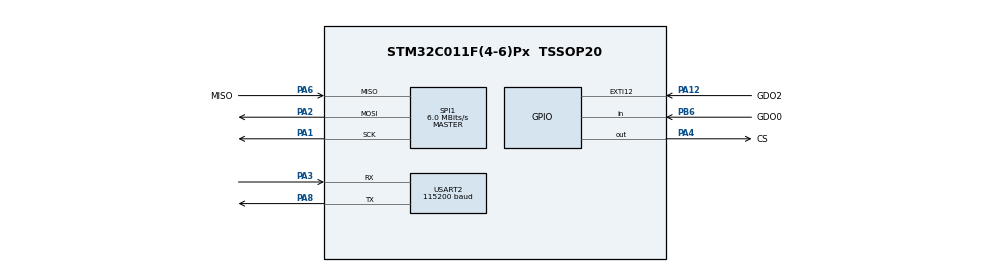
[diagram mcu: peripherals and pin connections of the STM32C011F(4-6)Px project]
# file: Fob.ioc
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Mcu.Family=STM32C0
Mcu.Name=STM32C011F(4-6)Px
Mcu.Package=TSSOP20
PA1.Mode=Full_Duplex_Master
PA1.Signal=SPI1_SCK
PA12\ [PA10].GPIO_Label=GDO2
PA12\ [PA10].Signal=GPXTI12
PA13.Mode=Serial_Wire
PA13.Signal=DEBUG_SWDIO
PA14-BOOT0.Mode=Serial_Wire
PA14-BOOT0.Signal=DEBUG_SWCLK
PA2.Mode=Full_Duplex_Master
PA2.Signal=SPI1_MOSI
PA3.Mode=Asynchronous
PA3.Signal=USART2_RX
PA4.GPIO_Label=CS
PA4.Signal=GPIO_Output
PA6.GPIO_Label=MISO
PA6.Mode=Full_Duplex_Master
PA6.Signal=SPI1_MISO
PA8.Mode=Asynchronous
PA8.Signal=USART2_TX
PB6.GPIO_Label=GDO0
PB6.Signal=GPIO_Input
ProjectManager.HeapSize=0x200
ProjectManager.StackSize=0x400
ProjectManager.TargetToolchain=STM32CubeIDE
RCC.ADCFreq_Value=12000000
RCC.AHBFreq_Value=12000000
RCC.CortexFreq_Value=12000000
RCC.EXTERNAL_CLOCK_VALUE=12288000
RCC.HCLKFreq_Value=12000000
RCC.HSE_VALUE=8000000
RCC.HSI_VALUE=48000000
RCC.LSE_VALUE=32768
RCC.SYSCLKFreq_VALUE=12000000
SPI1.CalculateBaudRate=6.0 MBits/s
SPI1.Direction=SPI_DIRECTION_2LINES
SPI1.Mode=SPI_MODE_MASTER
SPI1.VirtualType=VM_MASTER
USART2.BaudRate=115200
USART2.VirtualMode-Asynchronous=VM_ASYNC
board=custom

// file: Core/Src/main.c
/* USER CODE BEGIN Header */
/**
  ******************************************************************************
  * @file           : main.c
  * @brief          : Main program body
  ******************************************************************************
  * @attention
  *
  * Copyright (c) 2024 STMicroelectronics.
  * All rights reserved.
  *
  * This software is licensed under terms that can be found in the LICENSE file
  * in the root directory of this software component.
  * If no LICENSE file comes with this software, it is provided AS-IS.
  *
  ******************************************************************************
  */
/* USER CODE END Header */
#include "main.h"
#include "spi.h"
#include "usart.h"
#include "gpio.h"

/* USER CODE BEGIN Includes */
#include "cc1101.h"
/* USER CODE END Includes */

void SystemClock_Config(void);

int main(void)
{

  /* MCU Configuration--------------------------------------------------------*/

  /* Reset of all peripherals, Initializes the Flash interface and the Systick. */
  HAL_Init();

  /* Configure the system clock */
  SystemClock_Config();

  /* Initialize all configured peripherals */
  MX_GPIO_Init();
  MX_USART2_UART_Init();
  MX_SPI1_Init();
  /* USER CODE BEGIN 2 */

  // Power up the CC1101
  Power_up_reset();
  TI_init(&hspi1, CS_GPIO_Port, CS_Pin);

  uint8_t status;
  uint8_t ok = 7;
  uint8_t not_ok = 2;

  // Read the version, make sure it's 0x14
  status = TI_read_status(CCxxx0_VERSION);
  if (status==0x14){
  	  HAL_UART_Transmit(&huart2, &ok, sizeof(ok), 50); // Send to NUCLEO

  }
  else{
  	  HAL_UART_Transmit(&huart2, &not_ok, sizeof(not_ok), 50); // Send to NUCLEO
  }

  // Clear RX buffer

  // Send message: public key, "open", "u" = g^r,

  // Receive challenge

  // Calculate response

  // Send response

  // Power down

  /* USER CODE END 2 */

  /* Infinite loop */
  while (1)
  {

    /* USER CODE BEGIN 3 */
//	  HAL_Delay(10);
//	  status = TI_read_status(CCxxx0_PARTNUM);
//	  HAL_UART_Transmit(&huart2, &status, sizeof(status), 50); // Send to NUCLEO
//	  HAL_Delay(1000);
//
//	  status = TI_read_status(CCxxx0_FREQEST);
//	  HAL_UART_Transmit(&huart2, &status, sizeof(status), 50); // Send to NUCLEO
//	  HAL_Delay(10);

	  status = TI_read_status(CCxxx0_VERSION);
	  HAL_UART_Transmit(&huart2, &status, sizeof(status), 50); // Send to NUCLEO
	  HAL_Delay(10);

//	  status = TI_read_status(CCxxx0_RXBYTES);
//	  HAL_UART_Transmit(&huart2, &status, sizeof(status), 50); // Send to NUCLEO

  }
  /* USER CODE END 3 */
}

void SystemClock_Config(void)
{
  RCC_OscInitTypeDef RCC_OscInitStruct = {0};
  RCC_ClkInitTypeDef RCC_ClkInitStruct = {0};

  /** Initializes the RCC Oscillators according to the specified parameters
  * in the RCC_OscInitTypeDef structure.
  */
  RCC_OscInitStruct.OscillatorType = RCC_OSCILLATORTYPE_HSI;
  RCC_OscInitStruct.HSIState = RCC_HSI_ON;
  RCC_OscInitStruct.HSIDiv = RCC_HSI_DIV4;
  RCC_OscInitStruct.HSICalibrationValue = RCC_HSICALIBRATION_DEFAULT;
  if (HAL_RCC_OscConfig(&RCC_OscInitStruct) != HAL_OK)
  {
    Error_Handler();
  }

  /** Initializes the CPU, AHB and APB buses clocks
  */
  RCC_ClkInitStruct.ClockType = RCC_CLOCKTYPE_HCLK|RCC_CLOCKTYPE_SYSCLK
                              |RCC_CLOCKTYPE_PCLK1;
  RCC_ClkInitStruct.SYSCLKSource = RCC_SYSCLKSOURCE_HSI;
  RCC_ClkInitStruct.SYSCLKDivider = RCC_SYSCLK_DIV1;
  RCC_ClkInitStruct.AHBCLKDivider = RCC_HCLK_DIV1;
  RCC_ClkInitStruct.APB1CLKDivider = RCC_APB1_DIV1;

  if (HAL_RCC_ClockConfig(&RCC_ClkInitStruct, FLASH_LATENCY_0) != HAL_OK)
  {
    Error_Handler();
  }
}

void Error_Handler(void)
{
  __disable_irq();
  while (1)
  {
  }
}
